# STM32L4P5 register map
File version: 1.8
CPU: CM4 r0p1, little endian, MPU, FPU, 4 interrupt priority bits
Registers are 32-bit, read-write, reset 0x0 unless marked. A register's access mark holds for its fields unless they carry their own. Offsets are from the block's base; [hi:lo] are bit positions; lines under a group give offsets from that group; {n}, {i} and the like mark numbered series; <NAME> marks a mode.

## SAI1 — Serial audio interface
Base 0x40015400
Same registers: SAI2 0x40015800
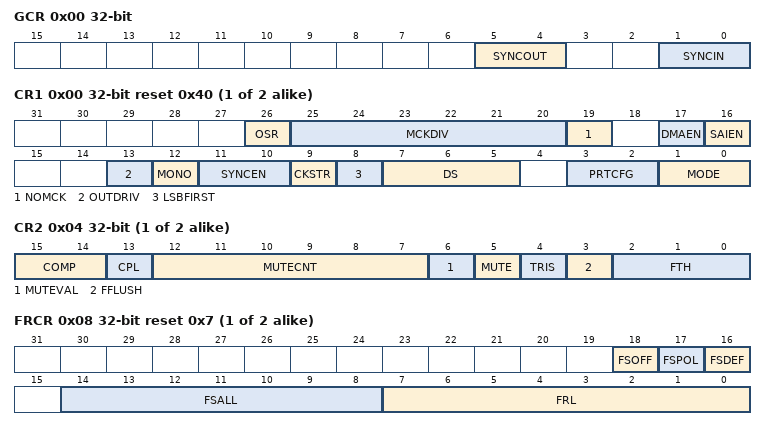
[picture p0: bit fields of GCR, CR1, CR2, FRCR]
0x00 GCR access not given — Global configuration register
  [5:4] SYNCOUT — Synchronization outputs
    0=Disabled (No synchronization output signals. SYNCOUT[1:0] should be configured as “No synchronization output signals” when audio block is configured as SPDIF); 1=Block A used for further synchronization for others SAI; 2=Block B used for further synchronization for others SAI
  [1:0] SYNCIN — Synchronization inputs
0x04 CH{x} (x=A,B; step 0x20) group — Cluster CH{x}, containing ?CR1, ?CR2, ?FRCR, ?SLOTR, ?IM, ?SR, ?CLRFR, ?DR
  0x00 CR1 reset 0x40 — AConfiguration register 1
    [26] OSR — Oversampling ratio for master clock
      0=Multiplier256 (Master clock frequency = FFS x 256); 1=Multiplier512 (Master clock frequency = FFS x 512)
    [25:20] MCKDIV — Master clock divider
    [19] NOMCK — No divider
      0=MasterClock (MCLK output is enabled. Forces the ratio between FS and MCLK to 256 or 512 according to the OSR value); 1=NoDiv (MCLK output enable set by the MCKEN bit (where present, else 0). Ratio between FS and MCLK depends on FRL.)
    [17] DMAEN — DMA enable
      0=Disabled (DMA disabled); 1=Enabled (DMA enabled)
    [16] SAIEN — Audio block A enable
      0=Disabled (SAI audio block disabled); 1=Enabled (SAI audio block enabled)
    [13] OUTDRIV — Output drive
      0=OnStart (Audio block output driven when SAIEN is set); 1=Immediately (Audio block output driven immediately after the setting of this bit)
    [12] MONO — Mono mode
      0=Stereo mode; 1=Mono mode
    [11:10] SYNCEN — Synchronization enable
      0=Asynchronous (audio sub-block in asynchronous mode); 1=Internal (audio sub-block is synchronous with the other internal audio sub-block. In this case, the audio sub-block must be configured in slave mode); 2=External (audio sub-block is synchronous with an external SAI embedded peripheral. In this case the audio sub-block should be configured in Slave mode)
    [9] CKSTR — Clock strobing edge
      0=FallingEdge (Data strobing edge is falling edge of SCK); 1=RisingEdge (Data strobing edge is rising edge of SCK)
    [8] LSBFIRST — Least significant bit first
      0=MsbFirst (Data are transferred with MSB first); 1=LsbFirst (Data are transferred with LSB first)
    [7:5] DS — Data size
      2=Bit8 (8 bits); 3=Bit10 (10 bits); 4=Bit16 (16 bits); 5=Bit20 (20 bits); 6=Bit24 (24 bits); 7=Bit32 (32 bits)
    [3:2] PRTCFG — Protocol configuration
      0=Free protocol. Free protocol allows to use the powerful configuration of the audio block to address a specific audio protocol; 1=SPDIF protocol; 2=AC’97 protocol
    [1:0] MODE — Audio block mode
      0=MasterTx (Master transmitter); 1=MasterRx (Master receiver); 2=SlaveTx (Slave transmitter); 3=SlaveRx (Slave receiver)
  0x04 CR2 — AConfiguration register 2
    [15:14] COMP — Companding mode
      0=No companding algorithm; 2=MuLaw (μ-Law algorithm); 3=A-Law algorithm
    [13] CPL — Complement bit
      0=OnesComplement (1’s complement representation); 1=TwosComplement (2’s complement representation)
    [12:7] MUTECNT — Mute counter
    [6] MUTEVAL — Mute value
      0=SendZero (Bit value 0 is sent during the mute mode); 1=SendLast (Last values are sent during the mute mode)
    [5] MUTE
      0=Disabled (No mute mode); 1=Enabled (Mute mode enabled)
    [4] TRIS — Tristate management on data line
      0=DrivenWhileInactive (SD output line is still driven by the SAI when a slot is inactive); 1=HighZ (SD output line is released (HI-Z) at the end of the last data bit of the last active slot if the next one is inactive)
    [3] FFLUSH wo — FIFO flush
      0=NoFlush (No FIFO flush); 1=Flush (FIFO flush. Programming this bit to 1 triggers the FIFO Flush. All the internal FIFO pointers (read and write) are cleared)
    [2:0] FTH — FIFO threshold
      0=Empty (FIFO empty); 1=Quarter1 (1⁄4 FIFO); 2=Quarter2 (1⁄2 FIFO); 3=Quarter3 (3⁄4 FIFO); 4=Full (FIFO full)
  0x08 FRCR reset 0x7 — AFRCR
    [18] FSOFF — Frame synchronization offset
      0=OnFirst (FS is asserted on the first bit of the slot 0); 1=BeforeFirst (FS is asserted one bit before the first bit of the slot 0)
    [17] FSPOL — Frame synchronization polarity
      0=FallingEdge (FS is active low (falling edge)); 1=RisingEdge (FS is active high (rising edge))
    [16] FSDEF — Frame synchronization definition
    [14:8] FSALL — Frame synchronization active level length
    [7:0] FRL — Frame length
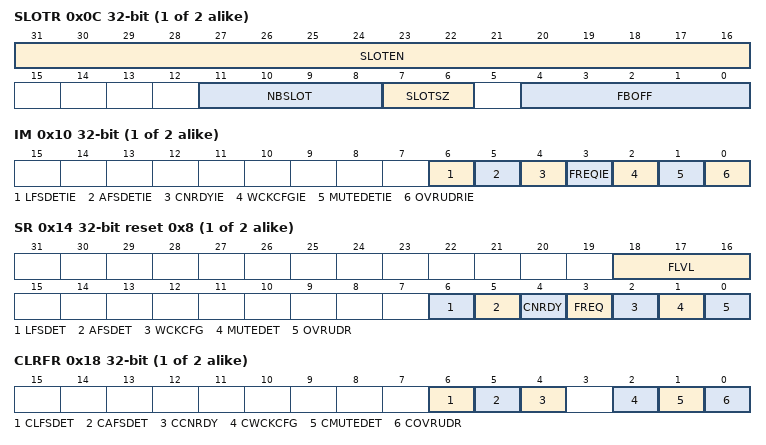
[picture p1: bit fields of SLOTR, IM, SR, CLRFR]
  0x0C SLOTR — ASlot register
    [31:16] SLOTEN — Slot enable
      0=Inactive slot; 1=Active slot
    [11:8] NBSLOT — Number of slots in an audio frame
    [7:6] SLOTSZ — Slot size
      0=DataSize (The slot size is equivalent to the data size (specified in DS[3:0] in the SAI_xCR1 register)); 1=Bit16 (16-bit); 2=Bit32 (32-bit)
    [4:0] FBOFF — First bit offset
  0x10 IM — AInterrupt mask register2
    [all] fields
      0=Disabled (Interrupt is disabled); 1=Enabled (Interrupt is enabled)
    [6] LFSDETIE — Late frame synchronization detection interrupt enable
    [5] AFSDETIE — Anticipated frame synchronization detection interrupt enable
    [4] CNRDYIE — Codec not ready interrupt enable
    [3] FREQIE — FIFO request interrupt enable
    [2] WCKCFGIE — Wrong clock configuration interrupt enable
    [1] MUTEDETIE — Mute detection interrupt enable
    [0] OVRUDRIE — Overrun/underrun interrupt enable
  0x14 SR ro reset 0x8 — AStatus register
    [18:16] FLVL — FIFO level threshold
      0=Empty (FIFO empty); 1=Quarter1 (FIFO <= 1⁄4 but not empty); 2=Quarter2 (1⁄4 < FIFO <= 1⁄2); 3=Quarter3 (1⁄2 < FIFO <= 3⁄4); 4=Quarter4 (3⁄4 < FIFO but not full); 5=Full (FIFO full)
    [6] LFSDET — Late frame synchronization detection
      0=NoError; 1=NoSync (Frame synchronization signal is not present at the right time)
    [5] AFSDET — Anticipated frame synchronization detection
      0=NoError; 1=EarlySync (Frame synchronization signal is detected earlier than expected)
    [4] CNRDY — Codec not ready
      0=Ready (External AC’97 Codec is ready); 1=NotReady (External AC’97 Codec is not ready)
    [3] FREQ — FIFO request
      0=NoRequest (No FIFO request); 1=Request (FIFO request to read or to write the SAI_xDR)
    [2] WCKCFG — Wrong clock configuration flag. This bit is read only
      0=Correct (Clock configuration is correct); 1=Wrong (Clock configuration does not respect the rule concerning the frame length specification)
    [1] MUTEDET — Mute detection
      0=No MUTE detection on the SD input line; 1=MUTE value detected on the SD input line (0 value) for a specified number of consecutive audio frame
    [0] OVRUDR — Overrun / underrun
      0=NoError (No overrun/underrun error); 1=Overrun/underrun error detection
  0x18 CLRFR wo — AClear flag register
    [6] CLFSDET — Clear late frame synchronization detection flag
      1=Clears the LFSDET flag
    [5] CAFSDET — Clear anticipated frame synchronization detection flag
      1=Clears the AFSDET flag
    [4] CCNRDY — Clear codec not ready flag
      1=Clears the CNRDY flag
    [2] CWCKCFG — Clear wrong clock configuration flag
      1=Clears the WCKCFG flag
    [1] CMUTEDET — Mute detection flag
      1=Clears the MUTEDET flag
    [0] COVRUDR — Clear overrun / underrun
      1=Clears the OVRUDR flag
  0x1C DR — AData register
    [31:0] DATA
